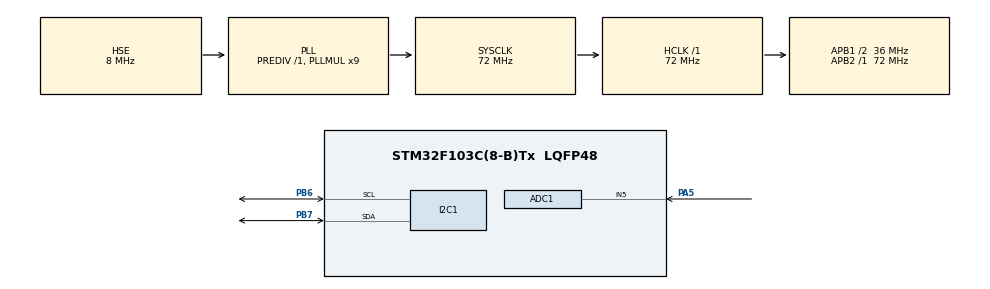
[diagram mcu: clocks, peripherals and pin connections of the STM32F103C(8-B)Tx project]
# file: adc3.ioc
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ADC1.Channel-0\#ChannelRegularConversion=ADC_CHANNEL_5
ADC1.ContinuousConvMode=ENABLE
ADC1.NbrOfConversionFlag=1
ADC1.Rank-0\#ChannelRegularConversion=1
ADC1.SamplingTime-0\#ChannelRegularConversion=ADC_SAMPLETIME_1CYCLE_5
ADC1.master=1
Dma.ADC1.0.Direction=DMA_PERIPH_TO_MEMORY
Dma.ADC1.0.Instance=DMA1_Channel1
Dma.ADC1.0.MemDataAlignment=DMA_MDATAALIGN_HALFWORD
Dma.ADC1.0.MemInc=DMA_MINC_ENABLE
Dma.ADC1.0.Mode=DMA_CIRCULAR
Dma.ADC1.0.PeriphDataAlignment=DMA_PDATAALIGN_HALFWORD
Dma.ADC1.0.PeriphInc=DMA_PINC_DISABLE
Dma.ADC1.0.Priority=DMA_PRIORITY_HIGH
Dma.Request0=ADC1
I2C1.I2C_Mode=I2C_Fast
I2C1.OwnAddress=0x7A
Mcu.Family=STM32F1
Mcu.Name=STM32F103C(8-B)Tx
Mcu.Package=LQFP48
NVIC.DMA1_Channel1_IRQn=true\:0\:0\:false\:false\:true\:false\:true\:true
NVIC.PriorityGroup=NVIC_PRIORITYGROUP_4
NVIC.TIM2_IRQn=true\:0\:0\:false\:false\:true\:true\:true\:true
PA13.Mode=Serial_Wire
PA13.Signal=SYS_JTMS-SWDIO
PA14.Mode=Serial_Wire
PA14.Signal=SYS_JTCK-SWCLK
PA5.Signal=ADCx_IN5
PB6.Mode=I2C
PB6.Signal=I2C1_SCL
PB7.Mode=I2C
PB7.Signal=I2C1_SDA
PD0-OSC_IN.Mode=HSE-External-Oscillator
PD0-OSC_IN.Signal=RCC_OSC_IN
PD1-OSC_OUT.Mode=HSE-External-Oscillator
PD1-OSC_OUT.Signal=RCC_OSC_OUT
ProjectManager.HeapSize=0x200
ProjectManager.StackSize=0x400
ProjectManager.TargetToolchain=STM32CubeIDE
RCC.ADCPresc=RCC_ADCPCLK2_DIV6
RCC.AHBFreq_Value=72000000
RCC.APB1CLKDivider=RCC_HCLK_DIV2
RCC.APB1Freq_Value=36000000
RCC.APB1TimFreq_Value=72000000
RCC.APB2Freq_Value=72000000
RCC.APB2TimFreq_Value=72000000
RCC.HCLKFreq_Value=72000000
RCC.PLLMUL=RCC_PLL_MUL9
RCC.PLLSourceVirtual=RCC_PLLSOURCE_HSE
RCC.SYSCLKFreq_VALUE=72000000
RCC.SYSCLKSource=RCC_SYSCLKSOURCE_PLLCLK
RCC.USBFreq_Value=72000000
SH.ADCx_IN5.0=ADC1_IN5,IN5
TIM2.Period=999
TIM2.Prescaler=71
VP_TIM2_VS_ClockSourceINT.Mode=Internal
board=custom

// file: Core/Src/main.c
/* USER CODE BEGIN Header */
/**
  ******************************************************************************
  * @file           : main.c
  * @brief          : Main program body
  ******************************************************************************
  * @attention
  *
  * Copyright (c) 2024 STMicroelectronics.
  * All rights reserved.
  *
  * This software is licensed under terms that can be found in the LICENSE file
  * in the root directory of this software component.
  * If no LICENSE file comes with this software, it is provided AS-IS.
  *
  ******************************************************************************
  */
/* USER CODE END Header */
#include "main.h"
#include "adc.h"
#include "dma.h"
#include "i2c.h"
#include "tim.h"
#include "gpio.h"

/* USER CODE BEGIN Includes */
#include "oled.h"
#include "math.h"
#include "stdio.h"
#include "font.h"
#include "string.h"
/* USER CODE END Includes */

/* USER CODE BEGIN PV */
uint16_t ADC_Value;    // ADC采样值
uint16_t ADC_DMA_Buffer;  // DMA缓冲区
float Voltage;         // 转换后的电压值
float Vol[128];        // 电压值缓存数组
uint8_t updateFlag;    // 显示更新标志
/* USER CODE END PV */

void SystemClock_Config(void);

/* USER CODE BEGIN 0 */
void Display_Init(void);
void Update_Display(void);
/* USER CODE END 0 */

int main(void)
{

  /* MCU Configuration--------------------------------------------------------*/

  /* Reset of all peripherals, Initializes the Flash interface and the Systick. */
  HAL_Init();

  /* Configure the system clock */
  SystemClock_Config();

  /* Initialize all configured peripherals */
  MX_GPIO_Init();
  MX_DMA_Init();
  MX_ADC1_Init();
  MX_I2C1_Init();
  MX_TIM2_Init();
  /* USER CODE BEGIN 2 */
  HAL_Delay(20);    // 等待OLED上电稳定
  OLED_Init();
//  Display_Init();   // 显示初始化界面

  /* 启动ADC DMA采样和定时器 */
  HAL_ADC_Start_DMA(&hadc1, (uint32_t*)&ADC_DMA_Buffer, 1);  // 启动ADC DMA模式
  HAL_TIM_Base_Start_IT(&htim2);
  /* USER CODE END 2 */

  /* Infinite loop */
  /* USER CODE BEGIN WHILE */
  while (1)
  {
	  if(updateFlag){
	       Update_Display();
	       updateFlag = 0;
	     }
	  HAL_Delay(1);
    /* USER CODE END WHILE */

  }
}

void SystemClock_Config(void)
{
  RCC_OscInitTypeDef RCC_OscInitStruct = {0};
  RCC_ClkInitTypeDef RCC_ClkInitStruct = {0};
  RCC_PeriphCLKInitTypeDef PeriphClkInit = {0};

  /** Initializes the RCC Oscillators according to the specified parameters
  * in the RCC_OscInitTypeDef structure.
  */
  RCC_OscInitStruct.OscillatorType = RCC_OSCILLATORTYPE_HSE;
  RCC_OscInitStruct.HSEState = RCC_HSE_ON;
  RCC_OscInitStruct.HSEPredivValue = RCC_HSE_PREDIV_DIV1;
  RCC_OscInitStruct.HSIState = RCC_HSI_ON;
  RCC_OscInitStruct.PLL.PLLState = RCC_PLL_ON;
  RCC_OscInitStruct.PLL.PLLSource = RCC_PLLSOURCE_HSE;
  RCC_OscInitStruct.PLL.PLLMUL = RCC_PLL_MUL9;
  if (HAL_RCC_OscConfig(&RCC_OscInitStruct) != HAL_OK)
  {
    Error_Handler();
  }

  /** Initializes the CPU, AHB and APB buses clocks
  */
  RCC_ClkInitStruct.ClockType = RCC_CLOCKTYPE_HCLK|RCC_CLOCKTYPE_SYSCLK
                              |RCC_CLOCKTYPE_PCLK1|RCC_CLOCKTYPE_PCLK2;
  RCC_ClkInitStruct.SYSCLKSource = RCC_SYSCLKSOURCE_PLLCLK;
  RCC_ClkInitStruct.AHBCLKDivider = RCC_SYSCLK_DIV1;
  RCC_ClkInitStruct.APB1CLKDivider = RCC_HCLK_DIV2;
  RCC_ClkInitStruct.APB2CLKDivider = RCC_HCLK_DIV1;

  if (HAL_RCC_ClockConfig(&RCC_ClkInitStruct, FLASH_LATENCY_2) != HAL_OK)
  {
    Error_Handler();
  }
  PeriphClkInit.PeriphClockSelection = RCC_PERIPHCLK_ADC;
  PeriphClkInit.AdcClockSelection = RCC_ADCPCLK2_DIV6;
  if (HAL_RCCEx_PeriphCLKConfig(&PeriphClkInit) != HAL_OK)
  {
    Error_Handler();
  }
}

/* USER CODE BEGIN 4 */
void Display_Init(void){
    OLED_NewFrame();
    // 初始采样并显示
    for(uint8_t i = 0; i < 128; i++)    {
      HAL_ADC_PollForConversion(&hadc1, 100);
      ADC_Value = HAL_ADC_GetValue(&hadc1);
      Vol[i] = (float)ADC_Value / 4095 * 3.3;
      OLED_SetPixel(i, 64 - (uint8_t)(Vol[i] * 19.09), 0);
    }
    OLED_ShowFrame();
  }

void Update_Display(void){
    OLED_NewFrame();
    // 数据左移并显示
    for(uint8_t i = 0; i < 127; i++){
        Vol[i] = Vol[i + 1];
        if(fabs(Vol[i] - Vol[i+1]) > 0.5){
            OLED_DrawLine(i, 64-(uint8_t)(Vol[i]*19.09),
                         i+1, 64-(uint8_t)(Vol[i+1]*19.09), 0);
        } else {
            OLED_SetPixel(i, 64-(uint8_t)(Vol[i]*19.09), 0);
        }
    }
    // 更新最新采样点 - 使用DMA获取的值
    Vol[127] = (float)ADC_Value / 4095 * 3.3;
    OLED_SetPixel(127, 64-(uint8_t)(Vol[127]*19.09), 0);

    OLED_ShowFrame();
}

void HAL_TIM_PeriodElapsedCallback(TIM_HandleTypeDef *htim){
	if(htim->Instance == TIM2){
    updateFlag = 1;
    }
}

// 添加DMA完成回调函数
void HAL_ADC_ConvCpltCallback(ADC_HandleTypeDef* hadc)
{
    if(hadc->Instance == ADC1)
    {
        ADC_Value = ADC_DMA_Buffer;  // 更新ADC值
    }
}
/* USER CODE END 4 */

void Error_Handler(void)
{
  __disable_irq();
  while (1)
  {
  }
}
